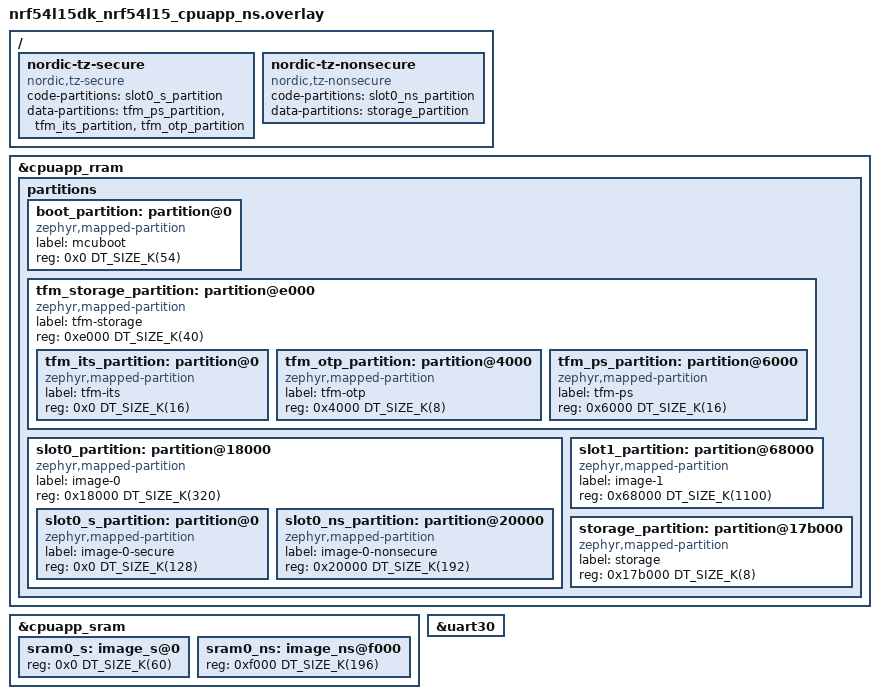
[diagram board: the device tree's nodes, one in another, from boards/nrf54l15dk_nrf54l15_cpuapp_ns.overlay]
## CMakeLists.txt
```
#
# Copyright (c) 2024 Nordic Semiconductor
#
# SPDX-License-Identifier: LicenseRef-Nordic-5-Clause
#

cmake_minimum_required(VERSION 3.20.0)

find_package(Zephyr REQUIRED HINTS $ENV{ZEPHYR_BASE})
project(compressed_update)

# This project uses orginal sdk-zephyr C source code
target_sources(app PRIVATE src/hook.c ${ZEPHYR_BASE}/samples/subsys/mgmt/mcumgr/smp_svr/src/main.c)
target_sources_ifdef(CONFIG_MCUMGR_TRANSPORT_BT app PRIVATE ${ZEPHYR_BASE}/samples/subsys/mgmt/mcumgr/smp_svr/src/bluetooth.c)
zephyr_link_libraries(MCUBOOT_BOOTUTIL)
```

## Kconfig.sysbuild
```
#
# Copyright (c) 2025 Nordic Semiconductor
#
# SPDX-License-Identifier: LicenseRef-Nordic-5-Clause
#

config PARTITION_MANAGER
	default n if SOC_SERIES_NRF52 || SOC_NRF54L15 || SOC_NRF54LM20A || SOC_NRF54LV10A || SOC_NRF54LC10A

source "share/sysbuild/Kconfig"
```

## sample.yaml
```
sample:
  description: >
    Demonstrates how to enable and use image compression within MCUboot,
    allowing for smaller application updates to be loaded to a device.
  name: MCUboot with decompression enabled sample

common:
  sysbuild: true
  tags:
    - sysbuild
    - ci_samples_nrf_compress
  harness: console
  harness_config:
    type: multi_line
    ordered: true
    regex:
      - "Starting bootloader"
      - "Jumping to the first image slot"
      - "smp_bt_sample: Advertising successfully started"
  timeout: 15
tests:
  sample.dfu.compressed_update:
    platform_allow:
      - nrf52840dk/nrf52840
      - nrf5340dk/nrf5340/cpuapp
      - nrf54l15dk/nrf54l15/cpuapp
      - nrf54lm20dk/nrf54lm20a/cpuapp
      - nrf54lm20dk/nrf54lm20b/cpuapp
      - nrf54ls05dk/nrf54ls05b/cpuapp
      - nrf54ls05dk/nrf54ls05a/cpuapp
      - nrf54lv10dk/nrf54lv10a/cpuapp
      - nrf54lc10dk/nrf54lc10a/cpuapp
      - nrf7120dk/nrf7120/cpuapp
    integration_platforms:
      - nrf52840dk/nrf52840
      - nrf5340dk/nrf5340/cpuapp
      - nrf54l15dk/nrf54l15/cpuapp
      - nrf54lm20dk/nrf54lm20a/cpuapp
      - nrf54lm20dk/nrf54lm20b/cpuapp
      - nrf54lv10dk/nrf54lv10a/cpuapp
      - nrf54lc10dk/nrf54lc10a/cpuapp
      - nrf7120dk/nrf7120/cpuapp
  sample.dfu.compressed_update.tfm:
    tags:
      - tfm
    extra_args:
      - FILE_SUFFIX=tfm
    platform_allow:
      - nrf54l15dk/nrf54l15/cpuapp/ns
      - nrf54lm20dk/nrf54lm20a/cpuapp/ns
      - nrf54lm20dk/nrf54lm20b/cpuapp/ns
      - nrf54lv10dk/nrf54lv10a/cpuapp/ns
      - nrf54lc10dk/nrf54lc10a/cpuapp/ns
    integration_platforms:
      - nrf54l15dk/nrf54l15/cpuapp/ns
      - nrf54lm20dk/nrf54lm20a/cpuapp/ns
      - nrf54lm20dk/nrf54lm20b/cpuapp/ns
      - nrf54lv10dk/nrf54lv10a/cpuapp/ns
      - nrf54lc10dk/nrf54lc10a/cpuapp/ns
```

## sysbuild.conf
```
#
# Copyright (c) 2024 Nordic Semiconductor
#
# SPDX-License-Identifier: LicenseRef-Nordic-5-Clause
#

SB_CONFIG_BOOTLOADER_MCUBOOT=y
SB_CONFIG_BOOT_SIGNATURE_TYPE_ECDSA_P256=y
SB_CONFIG_MCUBOOT_MODE_OVERWRITE_ONLY=y
SB_CONFIG_MCUBOOT_UPDATEABLE_IMAGES=1
SB_CONFIG_MCUBOOT_COMPRESSED_IMAGE_SUPPORT=y
# NETCORE_HCI_IPC is a choice entry that only exists for SoCs with a separate
# network core, so it selected nothing on the single-core boards. It is applied
# from the extra_args of the nRF5340 scenario instead.
# SB_CONFIG_NETCORE_HCI_IPC=y
```

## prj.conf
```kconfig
# Enable MCUmgr and dependencies.
CONFIG_NET_BUF=y
CONFIG_ZCBOR=y
CONFIG_CRC=y
CONFIG_MCUMGR=y
CONFIG_STREAM_FLASH=y
CONFIG_FLASH_MAP=y

# Some command handlers require a large stack.
CONFIG_SYSTEM_WORKQUEUE_STACK_SIZE=2304
CONFIG_MAIN_STACK_SIZE=2048

# Ensure an MCUboot-compatible binary is generated.
CONFIG_BOOTLOADER_MCUBOOT=y

# Enable flash operations.
CONFIG_FLASH=y

# Required by the `taskstat` command.
CONFIG_THREAD_MONITOR=y

# Support for taskstat command
CONFIG_MCUMGR_GRP_OS_TASKSTAT=y

# Enable statistics and statistic names.
CONFIG_STATS=y
CONFIG_STATS_NAMES=y

# Enable most core commands.
CONFIG_FLASH=y
CONFIG_IMG_MANAGER=y
CONFIG_MCUMGR_GRP_IMG=y
CONFIG_MCUMGR_GRP_OS=y
CONFIG_MCUMGR_GRP_STAT=y

# Enable logging
CONFIG_LOG=y
CONFIG_MCUBOOT_UTIL_LOG_LEVEL_WRN=y

# Disable debug logging
CONFIG_LOG_MAX_LEVEL=3

CONFIG_BT=y
CONFIG_BT_PERIPHERAL=y

# Allow for large Bluetooth data packets.
CONFIG_BT_L2CAP_TX_MTU=498
CONFIG_BT_BUF_ACL_RX_SIZE=502
CONFIG_BT_BUF_ACL_TX_SIZE=502
# BT_CTLR_DATA_LENGTH_MAX needs a controller in this image (BT_CTLR_DATA_LENGTH),
# which the nRF5340 application core does not have. It moved to
# overlay-bt-ctlr.conf, added by the local-controller scenarios only.
# CONFIG_BT_CTLR_DATA_LENGTH_MAX=251

# Enable the Bluetooth mcumgr transport (unauthenticated).
CONFIG_MCUMGR_TRANSPORT_BT=y
CONFIG_MCUMGR_TRANSPORT_BT_PERM_RW=y
CONFIG_MCUMGR_TRANSPORT_BT_CONN_PARAM_CONTROL=y

# Enable the Shell mcumgr transport.
CONFIG_BASE64=y
CONFIG_SHELL=y
CONFIG_SHELL_BACKEND_SERIAL=y
CONFIG_MCUMGR_TRANSPORT_SHELL=y
CONFIG_MCUMGR_TRANSPORT_SHELL_RX_BUF_COUNT=8

# Enable the mcumgr Packet Reassembly feature over Bluetooth and its configuration dependencies.
# MCUmgr buffer size is optimized to fit one SMP packet divided into five Bluetooth Write Commands,
# transmitted with the maximum possible MTU value: 498 bytes.
CONFIG_MCUMGR_TRANSPORT_BT_REASSEMBLY=y
CONFIG_MCUMGR_TRANSPORT_NETBUF_SIZE=2475
CONFIG_MCUMGR_GRP_OS_MCUMGR_PARAMS=y
CONFIG_MCUMGR_TRANSPORT_WORKQUEUE_STACK_SIZE=4608

# Disable Bluetooth ping support
CONFIG_BT_CTLR_LE_PING=n

# Disable shell commands that are not needed
CONFIG_CLOCK_CONTROL_NRF_SHELL=n
CONFIG_DEVICE_SHELL=n
CONFIG_DEVMEM_SHELL=n
CONFIG_FLASH_SHELL=n

CONFIG_MCUMGR_MGMT_NOTIFICATION_HOOKS=y
CONFIG_MCUMGR_GRP_IMG_STATUS_HOOKS=y
CONFIG_MCUMGR_GRP_IMG_IMAGE_SLOT_STATE_HOOK=y
CONFIG_MCUMGR_GRP_IMG_IMAGE_SLOT_STATE_STATES=20
```

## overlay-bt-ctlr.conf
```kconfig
# Applied only by the scenarios that run the Bluetooth controller in this image.
# BT_CTLR_DATA_LENGTH_MAX depends on BT_CTLR_DATA_LENGTH, which does not exist on
# the nRF5340 application core, where the controller lives on the network core.
CONFIG_BT_CTLR_DATA_LENGTH_MAX=251
```

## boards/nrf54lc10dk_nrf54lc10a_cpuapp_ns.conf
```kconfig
#
# Copyright (c) 2026 Nordic Semiconductor ASA
#
# SPDX-License-Identifier: LicenseRef-Nordic-5-Clause
#

CONFIG_BUILD_WITH_TFM=y
CONFIG_TFM_PROFILE_TYPE_MINIMAL=y
CONFIG_TFM_LOG_LEVEL_SILENCE=y
CONFIG_TFM_NRF_PROVISIONING=n
CONFIG_TFM_DUMMY_PROVISIONING=y
```

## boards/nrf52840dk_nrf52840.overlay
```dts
/*
 * Copyright (c) 2025 Nordic Semiconductor ASA
 *
 * SPDX-License-Identifier: LicenseRef-Nordic-5-Clause
 */

/delete-node/ &boot_partition;
/delete-node/ &slot0_partition;
/delete-node/ &slot1_partition;
/delete-node/ &storage_partition;

&flash0 {
	partitions {
		ranges;
		#address-cells = <1>;
		#size-cells = <1>;

		boot_partition: partition@0 {
			compatible = "zephyr,mapped-partition";
			label = "mcuboot";
			reg = <0x0 DT_SIZE_K(64)>;
		};

		slot0_partition: partition@10000 {
			compatible = "zephyr,mapped-partition";
			label = "image-0";
			reg = <0x10000 DT_SIZE_K(524)>;
		};

		slot1_partition: partition@93000 {
			compatible = "zephyr,mapped-partition";
			label = "image-1";
			reg = <0x93000 DT_SIZE_K(372)>;
		};

		storage_partition: partition@f0000 {
			compatible = "zephyr,mapped-partition";
			label = "storage";
			reg = <0xf0000 DT_SIZE_K(64)>;
		};
	};
};
```

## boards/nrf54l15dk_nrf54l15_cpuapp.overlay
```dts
/*
 * Copyright (c) 2025 Nordic Semiconductor ASA
 *
 * SPDX-License-Identifier: LicenseRef-Nordic-5-Clause
 */

/delete-node/ &boot_partition;
/delete-node/ &slot0_partition;
/delete-node/ &slot1_partition;
/delete-node/ &storage_partition;

&cpuapp_rram {
	partitions {
		ranges;
		#address-cells = <1>;
		#size-cells = <1>;

		boot_partition: partition@0 {
			compatible = "zephyr,mapped-partition";
			label = "mcuboot";
			reg = <0x0 DT_SIZE_K(44)>;
		};

		slot0_partition: partition@b000 {
			compatible = "zephyr,mapped-partition";
			label = "image-0";
			reg = <0xb000 DT_SIZE_K(784)>;
		};

		slot1_partition: partition@cf000 {
			compatible = "zephyr,mapped-partition";
			label = "image-1";
			reg = <0xcf000 DT_SIZE_K(536)>;
		};

		storage_partition: partition@155000 {
			compatible = "zephyr,mapped-partition";
			label = "storage";
			reg = <0x155000 DT_SIZE_K(64)>;
		};
	};
};
```

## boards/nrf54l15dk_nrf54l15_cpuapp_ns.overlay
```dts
/*
 * Copyright (c) 2026 Nordic Semiconductor ASA
 *
 * SPDX-License-Identifier: LicenseRef-Nordic-5-Clause
 */

/delete-node/ &slot0_s_partition;
/delete-node/ &storage_partition;
/delete-node/ &tfm_ps_partition;
/delete-node/ &tfm_its_partition;
/delete-node/ &tfm_otp_partition;

&cpuapp_rram {
	partitions {
		ranges;
		#address-cells = <1>;
		#size-cells = <1>;

		boot_partition: partition@0 {
			compatible = "zephyr,mapped-partition";
			label = "mcuboot";
			reg = <0x0 DT_SIZE_K(54)>;
		};

		tfm_storage_partition: partition@e000 {
			compatible = "zephyr,mapped-partition";
			label = "tfm-storage";
			reg = <0xe000 DT_SIZE_K(40)>;
			ranges = <0x0 0xe000 DT_SIZE_K(40)>;
			#address-cells = <1>;
			#size-cells = <1>;

			tfm_its_partition: partition@0 {
				compatible = "zephyr,mapped-partition";
				label = "tfm-its";
				reg = <0x0 DT_SIZE_K(16)>;
			};

			tfm_otp_partition: partition@4000 {
				compatible = "zephyr,mapped-partition";
				label = "tfm-otp";
				reg = <0x4000 DT_SIZE_K(8)>;
			};

			tfm_ps_partition: partition@6000 {
				compatible = "zephyr,mapped-partition";
				label = "tfm-ps";
				reg = <0x6000 DT_SIZE_K(16)>;
			};
		};

		slot0_partition: partition@18000 {
			compatible = "zephyr,mapped-partition";
			label = "image-0";
			reg = <0x18000 DT_SIZE_K(320)>;
			ranges = <0x0 0x18000 DT_SIZE_K(320)>;
			#address-cells = <1>;
			#size-cells = <1>;
		};

		slot1_partition: partition@68000 {
			compatible = "zephyr,mapped-partition";
			label = "image-1";
			reg = <0x68000 DT_SIZE_K(1100)>;
		};

		storage_partition: partition@17b000 {
			compatible = "zephyr,mapped-partition";
			label = "storage";
			reg = <0x17b000 DT_SIZE_K(8)>;
		};
	};
};

/delete-node/ &sram0_s;
/delete-node/ &sram0_ns;
/delete-node/ &slot0_ns_partition;

&cpuapp_sram {
	sram0_s: image_s@0 {
		reg = <0x0 DT_SIZE_K(60)>;
	};

	sram0_ns: image_ns@f000 {
		reg = <0xf000 DT_SIZE_K(196)>;
	};
};

&slot0_partition {
	slot0_s_partition: partition@0 {
		compatible = "zephyr,mapped-partition";
		label = "image-0-secure";
		reg = <0x0 DT_SIZE_K(128)>;
	};

	slot0_ns_partition: partition@20000 {
		compatible = "zephyr,mapped-partition";
		label = "image-0-nonsecure";
		reg = <0x20000 DT_SIZE_K(192)>;
	};
};

&uart30 {
	status = "okay";
};

/ {
	/delete-node/ nordic-tz-secure;
	/delete-node/ nordic-tz-nonsecure;

	nordic-tz-secure {
		compatible = "nordic,tz-secure";
		code-partitions = <&slot0_s_partition>;
		data-partitions = <&tfm_ps_partition>,
				  <&tfm_its_partition>,
				  <&tfm_otp_partition>;
	};

	nordic-tz-nonsecure {
		compatible = "nordic,tz-nonsecure";
		code-partitions = <&slot0_ns_partition>;
		data-partitions = <&storage_partition>;
	};
};
```

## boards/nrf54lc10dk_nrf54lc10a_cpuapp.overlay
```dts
/*
 * Copyright (c) 2026 Nordic Semiconductor ASA
 *
 * SPDX-License-Identifier: LicenseRef-Nordic-5-Clause
 */

/delete-node/ &boot_partition;
/delete-node/ &slot0_partition;
/delete-node/ &slot1_partition;

&cpuapp_rram {
	partitions {
		boot_partition: partition@0 {
			compatible = "zephyr,mapped-partition";
			label = "mcuboot";
			reg = <0x0 DT_SIZE_K(44)>;
		};

		slot0_partition: partition@b000 {
			compatible = "zephyr,mapped-partition";
			label = "image-0";
			reg = <0xb000 DT_SIZE_K(212)>;
		};

		slot1_partition: partition@40000 {
			compatible = "zephyr,mapped-partition";
			label = "image-1";
			reg = <0x40000 DT_SIZE_K(212)>;
		};
	};
};
```

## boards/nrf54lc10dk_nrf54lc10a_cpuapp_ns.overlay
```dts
/*
 * Copyright (c) 2026 Nordic Semiconductor ASA
 *
 * SPDX-License-Identifier: LicenseRef-Nordic-5-Clause
 */

/delete-node/ &slot0_partition;
/delete-node/ &storage_partition;
/delete-node/ &tfm_ps_partition;
/delete-node/ &tfm_its_partition;
/delete-node/ &tfm_otp_partition;

&cpuapp_rram {
	partitions {
		ranges;
		#address-cells = <1>;
		#size-cells = <1>;

		boot_partition: partition@0 {
			compatible = "zephyr,mapped-partition";
			label = "mcuboot";
			reg = <0x0 DT_SIZE_K(54)>;
		};

		tfm_storage_partition: partition@e000 {
			compatible = "zephyr,mapped-partition";
			label = "tfm-storage";
			reg = <0xe000 DT_SIZE_K(40)>;
			ranges = <0x0 0xe000 DT_SIZE_K(40)>;
			#address-cells = <1>;
			#size-cells = <1>;

			tfm_its_partition: partition@0 {
				compatible = "zephyr,mapped-partition";
				label = "tfm-its";
				reg = <0x0 DT_SIZE_K(16)>;
			};

			tfm_otp_partition: partition@4000 {
				compatible = "zephyr,mapped-partition";
				label = "tfm-otp";
				reg = <0x4000 DT_SIZE_K(8)>;
			};

			tfm_ps_partition: partition@6000 {
				compatible = "zephyr,mapped-partition";
				label = "tfm-ps";
				reg = <0x6000 DT_SIZE_K(16)>;
			};
		};

		slot0_partition: partition@18000 {
			compatible = "zephyr,mapped-partition";
			label = "image-0";
			reg = <0x18000 DT_SIZE_K(320)>;
			ranges = <0x0 0x18000 DT_SIZE_K(320)>;
			#address-cells = <1>;
			#size-cells = <1>;
		};

		slot1_partition: partition@68000 {
			compatible = "zephyr,mapped-partition";
			label = "image-1";
			reg = <0x68000 DT_SIZE_K(588)>;
		};

		storage_partition: partition@fb000 {
			compatible = "zephyr,mapped-partition";
			label = "storage";
			reg = <0xfb000 DT_SIZE_K(8)>;
		};
	};
};

/delete-node/ &sram0_s;
/delete-node/ &sram0_ns;
/delete-node/ &slot0_ns_partition;

&cpuapp_sram {
	sram0_s: image_s@0 {
		reg = <0x0 DT_SIZE_K(96)>;
	};

	sram0_ns: image_ns@18000 {
		reg = <0x18000 DT_SIZE_K(92)>;
	};
};

&slot0_partition {
	slot0_s_partition: partition@0 {
		compatible = "zephyr,mapped-partition";
		label = "image-0-secure";
		reg = <0x0 DT_SIZE_K(128)>;
	};

	slot0_ns_partition: partition@20000 {
		compatible = "zephyr,mapped-partition";
		label = "image-0-nonsecure";
		reg = <0x20000 DT_SIZE_K(192)>;
	};
};

&uart20 {
	status = "okay";
};

/ {
	nordic-tz-secure {
		compatible = "nordic,tz-secure";
		code-partitions = <&slot0_s_partition>;
		data-partitions = <&tfm_ps_partition>,
				  <&tfm_its_partition>,
				  <&tfm_otp_partition>;
	};

	nordic-tz-nonsecure {
		compatible = "nordic,tz-nonsecure";
		code-partitions = <&slot0_ns_partition>;
		data-partitions = <&storage_partition>;
	};
};
```

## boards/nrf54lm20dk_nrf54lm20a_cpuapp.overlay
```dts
/*
 * Copyright (c) 2025 Nordic Semiconductor ASA
 *
 * SPDX-License-Identifier: LicenseRef-Nordic-5-Clause
 */

/delete-node/ &boot_partition;
/delete-node/ &slot0_partition;
/delete-node/ &slot1_partition;
/delete-node/ &storage_partition;

&cpuapp_rram {
	partitions {
		ranges;
		#address-cells = <1>;
		#size-cells = <1>;

		boot_partition: partition@0 {
			compatible = "zephyr,mapped-partition";
			label = "mcuboot";
			reg = <0x0 DT_SIZE_K(64)>;
		};

		slot0_partition: partition@10000 {
			compatible = "zephyr,mapped-partition";
			label = "image-0";
			reg = <0x10000 DT_SIZE_K(1164)>;
		};

		slot1_partition: partition@133000 {
			compatible = "zephyr,mapped-partition";
			label = "image-1";
			reg = <0x133000 DT_SIZE_K(648)>;
		};

		storage_partition: partition@1d5000 {
			compatible = "zephyr,mapped-partition";
			label = "storage";
			reg = <0x1d5000 DT_SIZE_K(64)>;
		};
	};
};
```

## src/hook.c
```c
/*
 * Copyright (c) 2024 Nordic Semiconductor ASA
 *
 * SPDX-License-Identifier: LicenseRef-Nordic-5-Clause
 */

#include <zephyr/kernel.h>
#include <zephyr/init.h>
#include <zephyr/storage/flash_map.h>
#include <zephyr/mgmt/mcumgr/mgmt/mgmt.h>
#include <zephyr/mgmt/mcumgr/mgmt/callbacks.h>
#include <zephyr/mgmt/mcumgr/grp/img_mgmt/img_mgmt.h>
#include <zephyr/logging/log.h>
#include <zcbor_common.h>
#include <zcbor_encode.h>
#include <bootutil/image.h>

LOG_MODULE_REGISTER(compressed_update_sample, LOG_LEVEL_DBG);

#ifndef CONFIG_MCUMGR_GRP_IMG_FRUGAL_LIST
#define ZCBOR_ENCODE_FLAG(zse, label, value) \
	(zcbor_tstr_put_lit(zse, label) && zcbor_bool_put(zse, value))
#else
/* In "frugal" lists flags are added to response only when they evaluate to true */
/* Note that value is evaluated twice! */
#define ZCBOR_ENCODE_FLAG(zse, label, value) (!(value) || \
	 (zcbor_tstr_put_lit(zse, label) && zcbor_bool_put(zse, (value))))
#endif

static struct mgmt_callback image_slot_callback;
static struct k_work slot_output_work;

static void slot_output_handler(struct k_work *work)
{
	uint32_t slot;
	uint32_t slot_flags;
	int rc;

	for (size_t img = 0; img < CONFIG_UPDATEABLE_IMAGE_NUMBER; img++) {
		slot = (img * 2) + 1;

		rc = img_mgmt_read_info(slot, NULL, NULL, &slot_flags);
		if (rc) {
			continue;
		}

		slot_flags &= IMAGE_F_COMPRESSED_LZMA2 | IMAGE_F_COMPRESSED_ARM_THUMB_FLT;
		if (slot_flags == (IMAGE_F_COMPRESSED_LZMA2 | IMAGE_F_COMPRESSED_ARM_THUMB_FLT)) {
			LOG_INF("Secondary slot image %d is LZMA2 compressed with ARM thumb filter "
				"applied",
				img);
		} else if (slot_flags & IMAGE_F_COMPRESSED_LZMA2) {
			LOG_INF("Secondary slot image %d is LZMA2 compressed", img);
		} else {
			LOG_INF("Secondary slot image %d is uncompressed", img);
		}
	}
}

static enum mgmt_cb_return image_slot_state_cb(uint32_t event, enum mgmt_cb_return prev_status,
					       int32_t *rc, uint16_t *group, bool *abort_more,
					       void *data, size_t data_size)
{
	if (event == MGMT_EVT_OP_IMG_MGMT_IMAGE_SLOT_STATE) {
		/* Append a field indicating if the image in the slot is compressed */
		struct img_mgmt_state_slot_encode *slot_data =
						(struct img_mgmt_state_slot_encode *)data;

		*slot_data->ok = ZCBOR_ENCODE_FLAG(slot_data->zse, "compressed",
						  (slot_data->flags & IMAGE_F_COMPRESSED_LZMA2));
	} else if (event == MGMT_EVT_OP_IMG_MGMT_DFU_PENDING) {
		(void)k_work_submit(&slot_output_work);
	}

	return MGMT_CB_OK;
}

static int setup_slot_hook(void)
{
	/* Setup hook for when img mgmt image slot state is used and DFU pending callback */
	image_slot_callback.callback = image_slot_state_cb;
	image_slot_callback.event_id = MGMT_EVT_OP_IMG_MGMT_IMAGE_SLOT_STATE |
				       MGMT_EVT_OP_IMG_MGMT_DFU_PENDING;
	mgmt_callback_register(&image_slot_callback);
	k_work_init(&slot_output_work, slot_output_handler);

#if defined(CONFIG_OUTPUT_BOOT_MESSAGE)
	LOG_INF("Dummy message indicating new firmware is running...");
#endif

	return 0;
}

SYS_INIT(setup_slot_hook, APPLICATION, 0);
```
